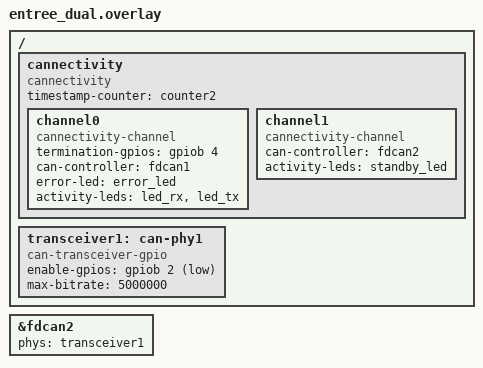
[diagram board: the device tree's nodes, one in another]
#include <zephyr/dt-bindings/gpio/gpio.h>
#include "../app.overlay"

/ {
	cannectivity: cannectivity {
		compatible = "cannectivity";
		timestamp-counter = <&counter2>;

		channel0 {
			compatible = "cannectivity-channel";
			termination-gpios = <&gpiob 4 GPIO_ACTIVE_HIGH>;
			can-controller = <&fdcan1>;
			error-led = <&error_led>;
			activity-leds = <&led_rx &led_tx>;
		};

		channel1 {
			compatible = "cannectivity-channel";
			can-controller = <&fdcan2>;
			activity-leds = <&standby_led>;
		};
	};

	transceiver1: can-phy1 {
		compatible = "can-transceiver-gpio";
		enable-gpios = <&gpiob 2 GPIO_ACTIVE_LOW>;
		max-bitrate = <5000000>;
		#phy-cells = <0>;
	};
};

&fdcan2 {
	phys = <&transceiver1>;
	status = "okay";
};
